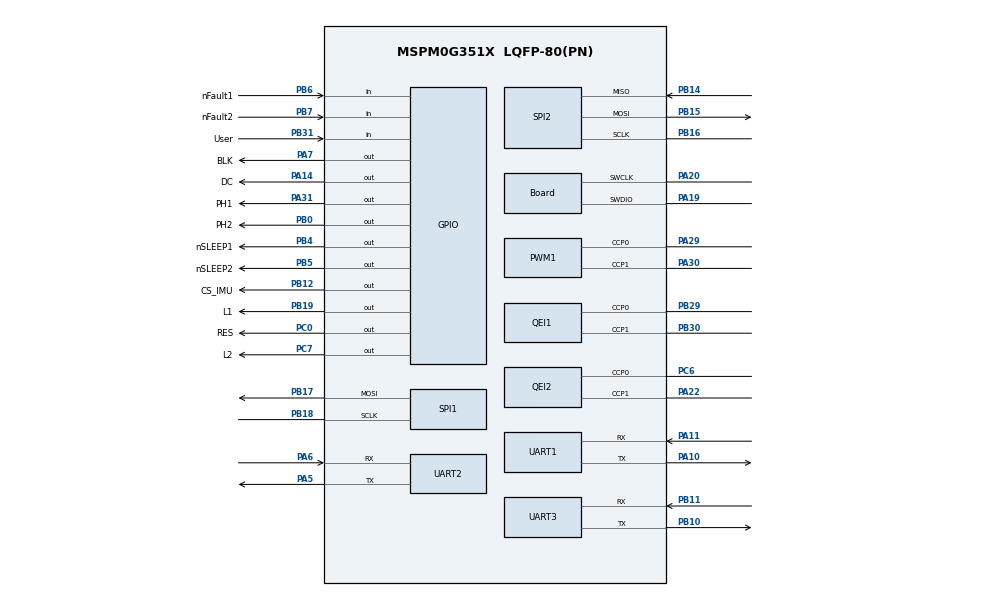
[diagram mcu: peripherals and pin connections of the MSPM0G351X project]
/**
 *
 * @cliArgs --device "MSPM0G351X" --part "Default" --package "LQFP-80(PN)" --product "mspm0_sdk@2.10.00.04"
 * @versions {"tool":"1.28.0+4712"}
 */

/**
 * Import the modules used in this configuration.
 */
const GPIO   = scripting.addModule("/ti/driverlib/GPIO", {}, false);
const GPIO1  = GPIO.addInstance();
const GPIO2  = GPIO.addInstance();
const GPIO3  = GPIO.addInstance();
const GPIO4  = GPIO.addInstance();
const GPIO5  = GPIO.addInstance();
const PWM    = scripting.addModule("/ti/driverlib/PWM", {}, false);
const PWM1   = PWM.addInstance();
const QEI    = scripting.addModule("/ti/driverlib/QEI", {}, false);
const QEI1   = QEI.addInstance();
const QEI2   = QEI.addInstance();
const SPI    = scripting.addModule("/ti/driverlib/SPI", {}, false);
const SPI1   = SPI.addInstance();
const SPI2   = SPI.addInstance();
const SYSCTL = scripting.addModule("/ti/driverlib/SYSCTL");
const TIMER  = scripting.addModule("/ti/driverlib/TIMER", {}, false);
const TIMER1 = TIMER.addInstance();
const TIMER2 = TIMER.addInstance();
const UART   = scripting.addModule("/ti/driverlib/UART", {}, false);
const UART1  = UART.addInstance();
const UART2  = UART.addInstance();
const UART3  = UART.addInstance();

/**
 * Write custom configuration values to the imported modules.
 */
const divider9       = system.clockTree["UDIV"];
divider9.divideValue = 2;

const multiplier2         = system.clockTree["PLL_QDIV"];
multiplier2.multiplyValue = 5;

const mux8       = system.clockTree["HSCLKMUX"];
mux8.inputSelect = "HSCLKMUX_SYSPLL0";

const mux10       = system.clockTree["MFPCLKMUX"];
mux10.inputSelect = "MFPCLKMUX_HFCLK";

GPIO1.$name                              = "LED";
GPIO1.associatedPins.create(2);
GPIO1.associatedPins[0].$name            = "L1";
GPIO1.associatedPins[0].internalResistor = "PULL_UP";
GPIO1.associatedPins[0].pin.$assign      = "PB19";
GPIO1.associatedPins[1].$name            = "L2";
GPIO1.associatedPins[1].internalResistor = "PULL_UP";
GPIO1.associatedPins[1].pin.$assign      = "PC7";

const Board                       = scripting.addModule("/ti/driverlib/Board", {}, false);
Board.peripheral.$assign          = "DEBUGSS";
Board.peripheral.swclkPin.$assign = "PA20";
Board.peripheral.swdioPin.$assign = "PA19";

GPIO2.$name                              = "Key";
GPIO2.associatedPins[0].$name            = "User";
GPIO2.associatedPins[0].direction        = "INPUT";
GPIO2.associatedPins[0].internalResistor = "PULL_UP";
GPIO2.associatedPins[0].pin.$assign      = "PB31";

GPIO3.$name                              = "LCD";
GPIO3.associatedPins.create(3);
GPIO3.associatedPins[0].$name            = "BLK";
GPIO3.associatedPins[0].pin.$assign      = "PA7";
GPIO3.associatedPins[1].$name            = "DC";
GPIO3.associatedPins[1].pin.$assign      = "PA14";
GPIO3.associatedPins[2].$name            = "RES";
GPIO3.associatedPins[2].pin.$assign      = "PC0";

GPIO4.$name                         = "IMU";
GPIO4.associatedPins[0].$name       = "CS_IMU";
GPIO4.associatedPins[0].pin.$assign = "PB12";

GPIO5.$name                                 = "Motor";
GPIO5.associatedPins.create(6);
GPIO5.associatedPins[0].$name               = "PH1";
GPIO5.associatedPins[0].pin.$assign         = "PA31";
GPIO5.associatedPins[1].$name               = "PH2";
GPIO5.associatedPins[1].pin.$assign         = "PB0";
GPIO5.associatedPins[2].$name               = "nSLEEP1";
GPIO5.associatedPins[2].pin.$assign         = "PB4";
GPIO5.associatedPins[3].$name               = "nSLEEP2";
GPIO5.associatedPins[3].pin.$assign         = "PB5";
GPIO5.associatedPins[4].$name               = "nFault1";
GPIO5.associatedPins[4].direction           = "INPUT";
GPIO5.associatedPins[4].internalResistor    = "PULL_UP";
GPIO5.associatedPins[4].pin.$assign         = "PB6";
GPIO5.associatedPins[5].$name               = "nFault2";
GPIO5.associatedPins[5].direction           = "INPUT";
GPIO5.associatedPins[5].internalResistor    = "PULL_UP";
GPIO5.associatedPins[5].pin.$assign         = "PB7";

PWM1.timerStartTimer                    = true;
PWM1.enableShadowLoad                   = true;
PWM1.$name                              = "PWMA";
PWM1.peripheral.$assign                 = "TIMG6";
PWM1.peripheral.ccp0Pin.$assign         = "PA29";
PWM1.peripheral.ccp1Pin.$assign         = "PA30";
PWM1.PWM_CHANNEL_0.$name                = "ti_driverlib_pwm_PWMTimerCC0";
PWM1.PWM_CHANNEL_0.dutyCycle            = 30;
PWM1.PWM_CHANNEL_1.$name                = "ti_driverlib_pwm_PWMTimerCC1";
PWM1.PWM_CHANNEL_1.dutyCycle            = 30;
PWM1.ccp0PinConfig.direction            = scripting.forceWrite("OUTPUT");
PWM1.ccp0PinConfig.hideOutputInversion  = scripting.forceWrite(false);
PWM1.ccp0PinConfig.onlyInternalResistor = scripting.forceWrite(false);
PWM1.ccp0PinConfig.passedPeripheralType = scripting.forceWrite("Digital");
PWM1.ccp0PinConfig.$name                = "ti_driverlib_gpio_GPIOPinGeneric11";
PWM1.ccp1PinConfig.direction            = scripting.forceWrite("OUTPUT");
PWM1.ccp1PinConfig.hideOutputInversion  = scripting.forceWrite(false);
PWM1.ccp1PinConfig.onlyInternalResistor = scripting.forceWrite(false);
PWM1.ccp1PinConfig.passedPeripheralType = scripting.forceWrite("Digital");
PWM1.ccp1PinConfig.$name                = "ti_driverlib_gpio_GPIOPinGeneric12";

QEI1.$name                      = "QEI_0";
QEI1.timerStartTimer            = true;
QEI1.peripheral.$assign         = "TIMG9";
QEI1.peripheral.ccp0Pin.$assign = "PB29";
QEI1.peripheral.ccp1Pin.$assign = "PB30";
QEI1.ccp0PinConfig.$name        = "ti_driverlib_gpio_GPIOPinGeneric2";
QEI1.ccp1PinConfig.$name        = "ti_driverlib_gpio_GPIOPinGeneric3";

QEI2.$name                      = "QEI_1";
QEI2.timerStartTimer            = true;
QEI2.peripheral.$assign         = "TIMG8";
QEI2.peripheral.ccp0Pin.$assign = "PC6";
QEI2.peripheral.ccp1Pin.$assign = "PA22";
QEI2.ccp0PinConfig.$name        = "ti_driverlib_gpio_GPIOPinGeneric9";
QEI2.ccp1PinConfig.$name        = "ti_driverlib_gpio_GPIOPinGeneric10";

SPI1.$name                      = "SPI_0";
SPI1.frameFormat                = "MOTO3";
SPI1.direction                  = "PICO";
SPI1.polarity                   = "1";
SPI1.phase                      = "1";
SPI1.sclkPinConfig.$name        = "ti_driverlib_gpio_GPIOPinGeneric4";
SPI1.mosiPinConfig.$name        = "ti_driverlib_gpio_GPIOPinGeneric5";
SPI1.peripheral.sclkPin.$assign = "PB18";
SPI1.peripheral.mosiPin.$assign = "PB17";

SPI2.$name                      = "SPI_1";
SPI2.frameFormat                = "MOTO3";
SPI2.polarity                   = "1";
SPI2.phase                      = "1";
SPI2.sclkPinConfig.$name        = "ti_driverlib_gpio_GPIOPinGeneric6";
SPI2.mosiPinConfig.$name        = "ti_driverlib_gpio_GPIOPinGeneric7";
SPI2.misoPinConfig.$name        = "ti_driverlib_gpio_GPIOPinGeneric8";
SPI2.peripheral.$assign         = "SPI1";
SPI2.peripheral.sclkPin.$assign = "PB16";
SPI2.peripheral.mosiPin.$assign = "PB15";
SPI2.peripheral.misoPin.$assign = "PB14";

SYSCTL.clockTreeEn = true;

TIMER1.timerStartTimer    = true;
TIMER1.timerClkPrescale   = 8;
TIMER1.interrupts         = ["ZERO"];
TIMER1.interruptPriority  = "2";
TIMER1.timerPeriod        = "0.002";
TIMER1.$name              = "TIMER_7";
TIMER1.peripheral.$assign = "TIMG7";

TIMER2.interrupts         = ["ZERO"];
TIMER2.interruptPriority  = "1";
TIMER2.timerPeriod        = "1ms";
TIMER2.timerStartTimer    = true;
TIMER2.$name              = "TIMER_12";
TIMER2.peripheral.$assign = "TIMG12";

UART1.$name                             = "UART_0";
UART1.enabledInterrupts                 = ["RX"];
UART1.targetBaudRate                    = 115200;
UART1.enabledDMATXTriggers              = "DL_UART_DMA_INTERRUPT_TX";
UART1.enabledDMARXTriggers              = "DL_UART_DMA_INTERRUPT_RX";
UART1.enableFIFO                        = true;
UART1.peripheral.rxPin.$assign          = "PA11";
UART1.peripheral.txPin.$assign          = "PA10";
UART1.txPinConfig.$name                 = "ti_driverlib_gpio_GPIOPinGeneric0";
UART1.rxPinConfig.$name                 = "ti_driverlib_gpio_GPIOPinGeneric1";
UART1.DMA_CHANNEL_TX.$name              = "DMA_CH0";
UART1.DMA_CHANNEL_TX.enableInterrupt    = true;
UART1.DMA_CHANNEL_TX.peripheral.$assign = "DMA_CH0";
UART1.DMA_CHANNEL_RX.$name              = "DMA_CH1";
UART1.DMA_CHANNEL_RX.peripheral.$assign = "DMA_CH1";

UART2.$name                             = "UART_1";
UART2.targetBaudRate                    = 115200;
UART2.enabledDMARXTriggers              = "DL_UART_DMA_INTERRUPT_RX";
UART2.enabledDMATXTriggers              = "DL_UART_DMA_INTERRUPT_TX";
UART2.enableFIFO                        = true;
UART2.peripheral.$assign                = "UART1";
UART2.peripheral.rxPin.$assign          = "PA6";
UART2.peripheral.txPin.$assign          = "PA5";
UART2.txPinConfig.$name                 = "ti_driverlib_gpio_GPIOPinGeneric13";
UART2.rxPinConfig.$name                 = "ti_driverlib_gpio_GPIOPinGeneric14";
UART2.DMA_CHANNEL_RX.enableInterrupt    = true;
UART2.DMA_CHANNEL_RX.$name              = "DMA_CH3";
UART2.DMA_CHANNEL_RX.peripheral.$assign = "DMA_CH3";
UART2.DMA_CHANNEL_TX.enableInterrupt    = true;
UART2.DMA_CHANNEL_TX.$name              = "DMA_CH4";
UART2.DMA_CHANNEL_TX.peripheral.$assign = "DMA_CH4";

UART3.$name                            = "UART_4";
UART3.enabledDMARXTriggers             = "DL_UART_DMA_INTERRUPT_RX";
UART3.enabledDMATXTriggers             = "DL_UART_DMA_INTERRUPT_TX";
UART3.targetBaudRate                   = 115200;
UART3.peripheral.$assign               = "UART4";
UART3.peripheral.rxPin.$assign         = "PB11";
UART3.peripheral.txPin.$assign         = "PB10";
UART3.txPinConfig.$name                = "ti_driverlib_gpio_GPIOPinGeneric15";
UART3.txPinConfig.direction            = scripting.forceWrite("OUTPUT");
UART3.txPinConfig.hideOutputInversion  = scripting.forceWrite(false);
UART3.txPinConfig.onlyInternalResistor = scripting.forceWrite(false);
UART3.txPinConfig.passedPeripheralType = scripting.forceWrite("Digital");
UART3.rxPinConfig.$name                = "ti_driverlib_gpio_GPIOPinGeneric16";
UART3.rxPinConfig.hideOutputInversion  = scripting.forceWrite(false);
UART3.rxPinConfig.onlyInternalResistor = scripting.forceWrite(false);
UART3.rxPinConfig.passedPeripheralType = scripting.forceWrite("Digital");
UART3.DMA_CHANNEL_RX.$name             = "DMA_CH5";
UART3.DMA_CHANNEL_RX.enableInterrupt   = true;
UART3.DMA_CHANNEL_RX.peripheral.$assign = "DMA_CH5";
UART3.DMA_CHANNEL_TX.$name             = "DMA_CH2";
UART3.DMA_CHANNEL_TX.enableInterrupt   = true;
UART3.DMA_CHANNEL_TX.peripheral.$assign = "DMA_CH2";

const ProjectConfig              = scripting.addModule("/ti/project_config/ProjectConfig", {}, false);
ProjectConfig.migrationCondition = true;

/**
 * Pinmux solution for unlocked pins/peripherals. This ensures that minor changes to the automatic solver in a future
 * version of the tool will not impact the pinmux you originally saw.  These lines can be completely deleted in order to
 * re-solve from scratch.
 */
QEI1.peripheral.$suggestSolution                 = "TIMG9";
QEI2.peripheral.$suggestSolution                 = "TIMG8";
SPI1.peripheral.$suggestSolution                 = "SPI0";
TIMER1.peripheral.$suggestSolution               = "TIMG7";
UART1.peripheral.$suggestSolution                = "UART0";
UART3.DMA_CHANNEL_RX.peripheral.$suggestSolution = "DMA_CH5";
UART3.DMA_CHANNEL_TX.peripheral.$suggestSolution = "DMA_CH2";
